# STM32G0B0 register map
File version: 1.0
CPU: CM0 r0p1, little endian, MPU, no FPU, 4 interrupt priority bits
Registers are 32-bit, read-write, reset 0x0 unless marked. A register's access mark holds for its fields unless they carry their own. Offsets are from the block's base; [hi:lo] are bit positions; {n}, {i} and the like mark numbered series; 'fields as' and 'values as' point back to an identical list.

## TIM1 (part 2 of 2) — Advanced-timers
Base 0x40012C00
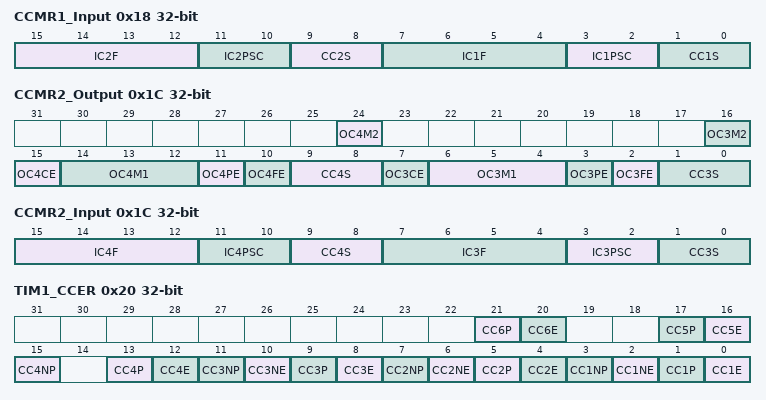
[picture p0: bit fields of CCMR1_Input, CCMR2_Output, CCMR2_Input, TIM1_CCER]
0x18 CCMR1_Input (alternate view of CCMR1_Output) — capture/compare mode register 1 (output mode)
  [15:12] IC2F — Input capture 2 filter Refer to IC1F[3:0] description.
  [11:10] IC2PSC — Input capture 2 prescaler Refer to IC1PSC[1:0] description.
  [9:8] CC2S — Capture/Compare 2 selection This bit-field defines the direction of the channel (input/output) as well as the used input. Note: CC2S bits are writable only when the channel is OFF (CC2E = '0â in TIMx_CCER).
    0=CC2 channel is configured as output; 1=CC2 channel is configured as input, IC2 is mapped on TI2; 2=CC2 channel is configured as input, IC2 is mapped on TI1; 3=CC2 channel is configured as input, IC2 is mapped on TRC. This mode is working only if an internal trigger input is selected through TS bit (TIMx_SMCR register)
  [7:4] IC1F — Input capture 1 filter This bit-field defines the frequency used to sample TI1 input and the length of the digital filter applied to TI1. The digital filter is made of an event counter in which N consecutive events are needed to validate a transition on the output:
    0=No filter, sampling is done at fDTS; 1=fSAMPLING=fCK_INT, N=2; 2=fSAMPLING=fCK_INT, N=4; 3=fSAMPLING=fCK_INT, N=8; 4=fSAMPLING=fDTS/2, N=6; 5=fSAMPLING=fDTS/2, N=8; 6=fSAMPLING=fDTS/4, N=6; 7=fSAMPLING=fDTS/4, N=8; 8=fSAMPLING=fDTS/8, N=6; 9=fSAMPLING=fDTS/8, N=8; 10=fSAMPLING=fDTS/16, N=5; 11=fSAMPLING=fDTS/16, N=6; 12=fSAMPLING=fDTS/16, N=8; 13=fSAMPLING=fDTS/32, N=5; 14=fSAMPLING=fDTS/32, N=6; 15=fSAMPLING=fDTS/32, N=8
  [3:2] IC1PSC — Input capture 1 prescaler This bit-field defines the ratio of the prescaler acting on CC1 input (IC1). The prescaler is reset as soon as CC1E=â0â (TIMx_CCER register).
    0=no prescaler, capture is done each time an edge is detected on the capture input; 1=capture is done once every 2 events; 2=capture is done once every 4 events; 3=capture is done once every 8 events
  [1:0] CC1S — Capture/Compare 1 Selection This bit-field defines the direction of the channel (input/output) as well as the used input. Note: CC1S bits are writable only when the channel is OFF (CC1E = '0â in TIMx_CCER).
    0=CC1 channel is configured as output; 1=CC1 channel is configured as input, IC1 is mapped on TI1; 2=CC1 channel is configured as input, IC1 is mapped on TI2; 3=CC1 channel is configured as input, IC1 is mapped on TRC. This mode is working only if an internal trigger input is selected through TS bit (TIMx_SMCR register)
0x1C CCMR2_Output — capture/compare mode register 2 (output mode)
  [24] OC4M2 — Output compare 4 mode Refer to OC3M[3:0] description.
  [16] OC3M2 — Output compare 3 mode Refer to OC1M[3:0] description.
  [15] OC4CE — Output compare 4 clear enable Refer to OC1CE description.
  [14:12] OC4M1 — Output compare 4 mode Refer to OC3M[3:0] description.
  [11] OC4PE — Output compare 4 preload enable Refer to OC1PE description.
  [10] OC4FE — Output compare 4 fast enable Refer to OC1FE description.
  [9:8] CC4S — Capture/Compare 4 selection This bit-field defines the direction of the channel (input/output) as well as the used input. Note: CC4S bits are writable only when the channel is OFF (CC4E = '0â in TIMx_CCER).
    0=CC4 channel is configured as output; 1=CC4 channel is configured as input, IC4 is mapped on TI4; 2=CC4 channel is configured as input, IC4 is mapped on TI3; 3=CC4 channel is configured as input, IC4 is mapped on TRC. This mode is working only if an internal trigger input is selected through TS bit (TIMx_SMCR register)
  [7] OC3CE — Output compare 3 clear enable Refer to OC1CE description.
  [6:4] OC3M1 — Output compare 3 mode Refer to OC1M[3:0] description.
  [3] OC3PE — Output compare 3 preload enable Refer to OC1PE description.
  [2] OC3FE — Output compare 3 fast enable Refer to OC1FE description.
  [1:0] CC3S — Capture/Compare 3 selection This bit-field defines the direction of the channel (input/output) as well as the used input. Note: CC3S bits are writable only when the channel is OFF (CC3E = '0â in TIMx_CCER).
    0=CC3 channel is configured as output; 1=CC3 channel is configured as input, IC3 is mapped on TI3; 2=CC3 channel is configured as input, IC3 is mapped on TI4; 3=CC3 channel is configured as input, IC3 is mapped on TRC. This mode is working only if an internal trigger input is selected through TS bit (TIMx_SMCR register)
0x1C CCMR2_Input (alternate view of CCMR2_Output) — capture/compare mode register 2 (output mode)
  [15:12] IC4F — Input capture 4 filter Refer to IC1F[3:0] description.
  [11:10] IC4PSC — Input capture 4 prescaler Refer to IC1PSC[1:0] description.
  [9:8] CC4S — Capture/Compare 4 selection This bit-field defines the direction of the channel (input/output) as well as the used input. Note: CC4S bits are writable only when the channel is OFF (CC4E = '0â in TIMx_CCER).
    values as CCMR2_Output.CC4S
  [7:4] IC3F — Input capture 3 filter Refer to IC1F[3:0] description.
  [3:2] IC3PSC — Input capture 3 prescaler Refer to IC1PSC[1:0] description.
  [1:0] CC3S — Capture/compare 3 selection This bit-field defines the direction of the channel (input/output) as well as the used input. Note: CC3S bits are writable only when the channel is OFF (CC3E = '0â in TIMx_CCER).
    values as CCMR2_Output.CC3S
0x20 TIM1_CCER — capture/compare enable register
  [4n-3] CC{n}P (n=2..6) — Capture/Compare {n} output polarity Refer to CC1P description
  [4n-4] CC{n}E (n=2..6) — Capture/Compare {n} output enable Refer to CC1E description
  [15] CC4NP — Capture/Compare 4 complementary output polarity Refer to CC1NP description
  [11] CC3NP — Capture/Compare 3 complementary output polarity Refer to CC1NP description
  [10] CC3NE — Capture/Compare 3 complementary output enable Refer to CC1NE description
  [7] CC2NP — Capture/Compare 2 complementary output polarity Refer to CC1NP description
  [6] CC2NE — Capture/Compare 2 complementary output enable Refer to CC1NE description
  [3] CC1NP — Capture/Compare 1 complementary output polarity CC1 channel configured as output: CC1 channel configured as input: This bit is used in conjunction with CC1P to define the polarity of TI1FP1 and TI2FP1. Refer to CC1P description. Note: This bit is not writable as soon as LOCK level 2 or 3 has been programmed (LOCK bits in TIMx_BDTR register) and CC1S=â00â (channel configured as output). On channels having a complementary output, this bit is preloaded. If the CCPC bit is set in the TIMx_CR2 register then the CC1NP active bit takes the new value from the preloaded bit only when a Commutation event is generated.
    0=OC1N active high; 1=OC1N active low
  [2] CC1NE — Capture/Compare 1 complementary output enable On channels having a complementary output, this bit is preloaded. If the CCPC bit is set in the TIMx_CR2 register then the CC1NE active bit takes the new value from the preloaded bit only when a Commutation event is generated.
    0=Off - OC1N is not active. OC1N level is then function of MOE, OSSI, OSSR, OIS1, OIS1N and CC1E bits.; 1=On - OC1N signal is output on the corresponding output pin depending on MOE, OSSI, OSSR, OIS1, OIS1N and CC1E bits
  [1] CC1P — Capture/Compare 1 output polarity When CC1 channel is configured as input, both CC1NP/CC1P bits select the active polarity of TI1FP1 and TI2FP1 for trigger or capture operations. CC1NP=0, CC1P=0: non-inverted/rising edge. The circuit is sensitive to TIxFP1 rising edge (capture or trigger operations in reset, external clock or trigger mode), TIxFP1 is not inverted (trigger operation in gated mode or encoder mode). CC1NP=0, CC1P=1: inverted/falling edge. The circuit is sensitive to TIxFP1 falling edge (capture or trigger operations in reset, external clock or trigger mode), TIxFP1 is inverted (trigger operation in gated mode or encoder mode). CC1NP=1, CC1P=1: non-inverted/both edges/ The circuit is sensitive to both TIxFP1 rising and falling edges (capture or trigger operations in reset, external clock or trigger mode), TIxFP1is not inverted (trigger operation in gated mode). This configuration must not be used in encoder mode. CC1NP=1, CC1P=0: The configuration is reserved, it must not be used. Note: This bit is not writable as soon as LOCK level 2 or 3 has been programmed (LOCK bits in TIMx_BDTR register). On channels having a complementary output, this bit is preloaded. If the CCPC bit is set in the TIMx_CR2 register then the CC1P active bit takes the new value from the preloaded bit only when a Commutation event is generated.
    0=OC1 active high (output mode) / Edge sensitivity selection (input mode, see below); 1=OC1 active low (output mode) / Edge sensitivity selection (input mode, see below)
  [0] CC1E — Capture/Compare 1 output enable When CC1 channel is configured as output, the OC1 level depends on MOE, OSSI, OSSR, OIS1, OIS1N and CC1NE bits, regardless of the CC1E bits state. Refer to for details. Note: On channels having a complementary output, this bit is preloaded. If the CCPC bit is set in the TIMx_CR2 register then the CC1E active bit takes the new value from the preloaded bit only when a Commutation event is generated.
    0=Capture mode disabled / OC1 is not active (see below); 1=Capture mode enabled / OC1 signal is output on the corresponding output pin
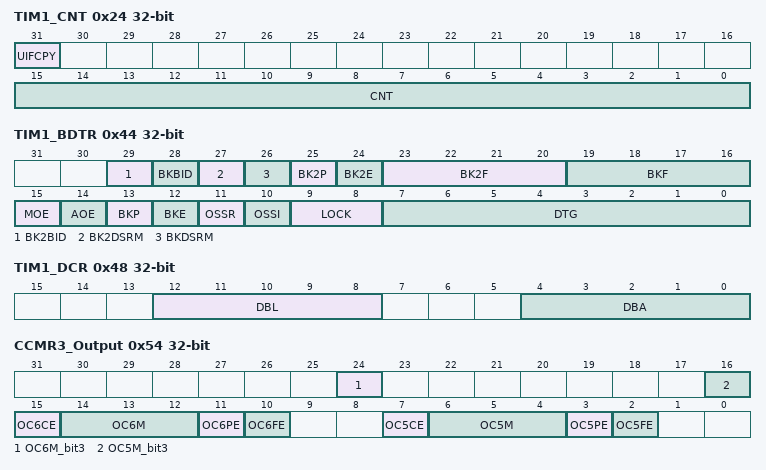
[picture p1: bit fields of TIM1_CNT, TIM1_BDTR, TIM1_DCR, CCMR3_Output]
0x24 TIM1_CNT access per field — counter
  [31] UIFCPY ro — UIF copy This bit is a read-only copy of the UIF bit of the TIMx_ISR register. If the UIFREMAP bit in the TIMxCR1 is reset, bit 31 is reserved and read at 0.
  [15:0] CNT rw — Counter value
0x28 TIM1_PSC — prescaler
  [15:0] PSC — Prescaler value The counter clock frequency (CK_CNT) is equal to fCK_PSC / (PSC[15:0] + 1). PSC contains the value to be loaded in the active prescaler register at each update event (including when the counter is cleared through UG bit of TIMx_EGR register or through trigger controller when configured in âreset modeâ).
0x2C TIM1_ARR reset 0xFFFF — auto-reload register
  [15:0] ARR — Auto-reload value ARR is the value to be loaded in the actual auto-reload register. Refer to the for more details about ARR update and behavior. The counter is blocked while the auto-reload value is null.
0x30 TIM1_RCR — repetition counter register
  [15:0] REP — Repetition counter value
0x34 TIM1_CCR1 — capture/compare register 1
  [15:0] CCR1 — Capture/Compare 1 value
0x38 TIM1_CCR2 — capture/compare register 2
  [15:0] CCR2 — Capture/Compare 2 value
0x3C TIM1_CCR3 — capture/compare register 3
  [15:0] CCR3 — Capture/Compare value
0x40 TIM1_CCR4 — capture/compare register 4
  [15:0] CCR4 — Capture/Compare value
0x44 TIM1_BDTR — break and dead-time register
  [29] BK2BID — Break2 bidirectional Refer to BKBID description
  [28] BKBID — Break Bidirectional In the bidirectional mode (BKBID bit set to 1), the break input is configured both in input mode and in open drain output mode. Any active break event asserts a low logic level on the Break input to indicate an internal break event to external devices. Note: This bit cannot be modified as long as LOCK level 1 has been programmed (LOCK bits in TIMx_BDTR register). Note: Any write operation to this bit takes a delay of 1 APB clock cycle to become effective.
    0=Break input BRK in input mode; 1=Break input BRK in bidirectional mode
  [27] BK2DSRM — Break2 Disarm Refer to BKDSRM description
  [26] BKDSRM — Break Disarm This bit is cleared by hardware when no break source is active. The BKDSRM bit must be set by software to release the bidirectional output control (open-drain output in Hi-Z state) and then be polled it until it is reset by hardware, indicating that the fault condition has disappeared. Note: Any write operation to this bit takes a delay of 1 APB clock cycle to become effective.
    0=Break input BRK is armed; 1=Break input BRK is disarmed
  [25] BK2P — Break 2 polarity Note: This bit cannot be modified as long as LOCK level 1 has been programmed (LOCK bits in TIMx_BDTR register). Note: Any write operation to this bit takes a delay of 1 APB clock cycle to become effective.
    0=Break input BRK2 is active low; 1=Break input BRK2 is active high
  [24] BK2E — Break 2 enable Note: The BRK2 must only be used with OSSR = OSSI = 1. Note: This bit cannot be modified when LOCK level 1 has been programmed (LOCK bits in TIMx_BDTR register). Note: Any write operation to this bit takes a delay of 1 APB clock cycle to become effective.
    0=Break input BRK2 disabled; 1=Break input BRK2 enabled
  [23:20] BK2F — Break 2 filter This bit-field defines the frequency used to sample BRK2 input and the length of the digital filter applied to BRK2. The digital filter is made of an event counter in which N consecutive events are needed to validate a transition on the output: Note: This bit cannot be modified when LOCK level 1 has been programmed (LOCK bits in TIMx_BDTR register).
    0=No filter, BRK2 acts asynchronously; 1=fSAMPLING=fCK_INT, N=2; 2=fSAMPLING=fCK_INT, N=4; 3=fSAMPLING=fCK_INT, N=8; 4=fSAMPLING=fDTS/2, N=6; 5=fSAMPLING=fDTS/2, N=8; 6=fSAMPLING=fDTS/4, N=6; 7=fSAMPLING=fDTS/4, N=8; 8=fSAMPLING=fDTS/8, N=6; 9=fSAMPLING=fDTS/8, N=8; 10=fSAMPLING=fDTS/16, N=5; 11=fSAMPLING=fDTS/16, N=6; 12=fSAMPLING=fDTS/16, N=8; 13=fSAMPLING=fDTS/32, N=5; 14=fSAMPLING=fDTS/32, N=6; 15=fSAMPLING=fDTS/32, N=8
  [19:16] BKF — Break filter This bit-field defines the frequency used to sample BRK input and the length of the digital filter applied to BRK. The digital filter is made of an event counter in which N consecutive events are needed to validate a transition on the output: Note: This bit cannot be modified when LOCK level 1 has been programmed (LOCK bits in TIMx_BDTR register).
    0=No filter, BRK acts asynchronously; 1=fSAMPLING=fCK_INT, N=2; 2=fSAMPLING=fCK_INT, N=4; 3=fSAMPLING=fCK_INT, N=8; 4=fSAMPLING=fDTS/2, N=6; 5=fSAMPLING=fDTS/2, N=8; 6=fSAMPLING=fDTS/4, N=6; 7=fSAMPLING=fDTS/4, N=8; 8=fSAMPLING=fDTS/8, N=6; 9=fSAMPLING=fDTS/8, N=8; 10=fSAMPLING=fDTS/16, N=5; 11=fSAMPLING=fDTS/16, N=6; 12=fSAMPLING=fDTS/16, N=8; 13=fSAMPLING=fDTS/32, N=5; 14=fSAMPLING=fDTS/32, N=6; 15=fSAMPLING=fDTS/32, N=8
  [15] MOE — Main output enable This bit is cleared asynchronously by hardware as soon as one of the break inputs is active (BRK or BRK2). It is set by software or automatically depending on the AOE bit. It is acting only on the channels which are configured in output. In response to a break event or if MOE is written to 0: OC and OCN outputs are disabled or forced to idle state depending on the OSSI bit. See OC/OCN enable description for more details (enable register (TIM1_CCERTIMx_CCER)N/A).
    0=In response to a break 2 event. OC and OCN outputs are disabled; 1=OC and OCN outputs are enabled if their respective enable bits are set (CCxE, CCxNE in TIMx_CCER register)
  [14] AOE — Automatic output enable Note: This bit can not be modified as long as LOCK level 1 has been programmed (LOCK bits in TIMx_BDTR register).
    0=MOE can be set only by software; 1=MOE can be set by software or automatically at the next update event (if none of the break inputs BRK and BRK2 is active)
  [13] BKP — Break polarity Note: This bit can not be modified as long as LOCK level 1 has been programmed (LOCK bits in TIMx_BDTR register). Note: Any write operation to this bit takes a delay of 1 APB clock cycle to become effective.
    0=Break input BRK is active low; 1=Break input BRK is active high
  [12] BKE — Break enable This bit enables the complete break protection (including all sources connected to bk_acth and BKIN sources, as per ). Note: This bit cannot be modified when LOCK level 1 has been programmed (LOCK bits in TIMx_BDTR register). Note: Any write operation to this bit takes a delay of 1 APB clock cycle to become effective.
    0=Break function disabled; 1=Break function enabled
  [11] OSSR — Off-state selection for Run mode This bit is used when MOE=1 on channels having a complementary output which are configured as outputs. OSSR is not implemented if no complementary output is implemented in the timer. See OC/OCN enable description for more details (enable register (TIM1_CCERTIMx_CCER)N/A). Note: This bit can not be modified as soon as the LOCK level 2 has been programmed (LOCK bits in TIMx_BDTR register).
    0=When inactive, OC/OCN outputs are disabled (the timer releases the output control which is taken over by the GPIO logic, which forces a Hi-Z state); 1=When inactive, OC/OCN outputs are enabled with their inactive level as soon as CCxE=1 or CCxNE=1 (the output is still controlled by the timer)
  [10] OSSI — Off-state selection for Idle mode This bit is used when MOE=0 due to a break event or by a software write, on channels configured as outputs. See OC/OCN enable description for more details (enable register (TIM1_CCERTIMx_CCER)N/A). Note: This bit can not be modified as soon as the LOCK level 2 has been programmed (LOCK bits in TIMx_BDTR register).
    0=When inactive, OC/OCN outputs are disabled (the timer releases the output control which is taken over by the GPIO logic and which imposes a Hi-Z state); 1=When inactive, OC/OCN outputs are first forced with their inactive level then forced to their idle level after the deadtime. The timer maintains its control over the output.
  [9:8] LOCK — Lock configuration These bits offer a write protection against software errors. Note: The LOCK bits can be written only once after the reset. Once the TIMx_BDTR register has been written, their content is frozen until the next reset.
    0=LOCK OFF - No bit is write protected; 1=LOCK Level 1 = DTG bits in TIMx_BDTR register, OISx and OISxN bits in TIMx_CR2 register and BK2BID, BKBID, BK2DSRM, BKDSRM, BK2P, BK2E, BK2F[3:0], BKF[3:0], AOE, BKP, BKE, OSSI, OSSR and DTG[7:0] bits in TIMx_BDTR register can no longer be written; 2=LOCK Level 2 = LOCK Level 1 + CC Polarity bits (CCxP/CCxNP bits in TIMx_CCER register, as long as the related channel is configured in output through the CCxS bits) as well as OSSR and OSSI bits can no longer be written; 3=LOCK Level 3 = LOCK Level 2 + CC Control bits (OCxM and OCxPE bits in TIMx_CCMRx registers, as long as the related channel is configured in output through the CCxS bits) can no longer be written
  [7:0] DTG — Dead-time generator setup This bit-field defines the duration of the dead-time inserted between the complementary outputs. DT correspond to this duration. DTG[7:5]=0xx => DT=DTG[7:0]x tDTG with tDTG=tDTS. DTG[7:5]=10x => DT=(64+DTG[5:0])xtDTG with tDTG=2xtDTS. DTG[7:5]=110 => DT=(32+DTG[4:0])xtDTG with tDTG=8xtDTS. DTG[7:5]=111 => DT=(32+DTG[4:0])xtDTG with tDTG=16xtDTS. Example if tDTS=125Â ns (8Â MHz), dead-time possible values are: 0 to 15875Â ns by 125Â ns steps, 16Â Î¼s to 31750Â nsÂ by 250Â ns steps, 32Â Î¼s to 63Â Î¼s by 1Â Î¼s steps, 64Â Î¼s to 126Â Î¼s by 2Â Î¼s steps Note: This bit-field can not be modified as long as LOCK level 1, 2 or 3 has been programmed (LOCK bits in TIMx_BDTR register).
0x48 TIM1_DCR — DMA control register
  [12:8] DBL — DMA burst length This 5-bit vector defines the length of DMA transfers (the timer recognizes a burst transfer when a read or a write access is done to the TIMx_DMAR address), i.e. the number of transfers. Transfers can be in half-words or in bytes (see example below). ... Example: Let us consider the following transfer: DBL = 7 bytes & DBA = TIMx_CR1. If DBL = 7 bytes and DBA = TIMx_CR1 represents the address of the byte to be transferred, the address of the transfer should be given by the following equation: (TIMx_CR1 address) + DBA + (DMA index), where DMA index = DBL In this example, 7 bytes are added to (TIMx_CR1 address) + DBA, which gives us the address from/to which the data is copied. In this case, the transfer is done to 7 registers starting from the following address: (TIMx_CR1 address) + DBA According to the configuration of the DMA Data Size, several cases may occur: If the DMA Data Size is configured in half-words, 16-bit data is transferred to each of the 7 registers. If the DMA Data Size is configured in bytes, the data is also transferred to 7 registers: the first register contains the first MSB byte, the second register, the first LSB byte and so on. So with the transfer Timer, one also has to specify the size of data transferred by DMA.
    0=1 transfer; 1=2 transfers; 2=3 transfers; 17=18 transfers
  [4:0] DBA — DMA base address This 5-bits vector defines the base-address for DMA transfers (when read/write access are done through the TIMx_DMAR address). DBA is defined as an offset starting from the address of the TIMx_CR1 register. Example: ...
    0=TIMx_CR1,; 1=TIMx_CR2,; 2=TIMx_SMCR,
0x4C TIM1_DMAR — DMA address for full transfer
  [31:0] DMAB — DMA register for burst accesses A read or write operation to the DMAR register accesses the register located at the address (TIMx_CR1 address) + (DBA + DMA index) x 4 where TIMx_CR1 address is the address of the control register 1, DBA is the DMA base address configured in TIMx_DCR register, DMA index is automatically controlled by the DMA transfer, and ranges from 0 to DBL (DBL configured in TIMx_DCR).
0x50 TIM1_OR1 — option register 1
  [0] OCREF_CLR — Ocref_clr source selection This bit selects the ocref_clr input source.
    0=COMP1 output is connected to the OCREF_CLR input; 1=COMP2 output is connected to the OCREF_CLR input
0x54 CCMR3_Output — capture/compare mode register 2 (output mode)
  [24] OC6M_bit3 — Output Compare 6 mode bit 3
  [16] OC5M_bit3 — Output Compare 5 mode bit 3
  [15] OC6CE — Output compare 6 clear enable
  [14:12] OC6M — Output compare 6 mode
  [11] OC6PE — Output compare 6 preload enable
  [10] OC6FE — Output compare 6 fast enable
  [7] OC5CE — Output compare 5 clear enable
  [6:4] OC5M — Output compare 5 mode
  [3] OC5PE — Output compare 5 preload enable
  [2] OC5FE — Output compare 5 fast enable
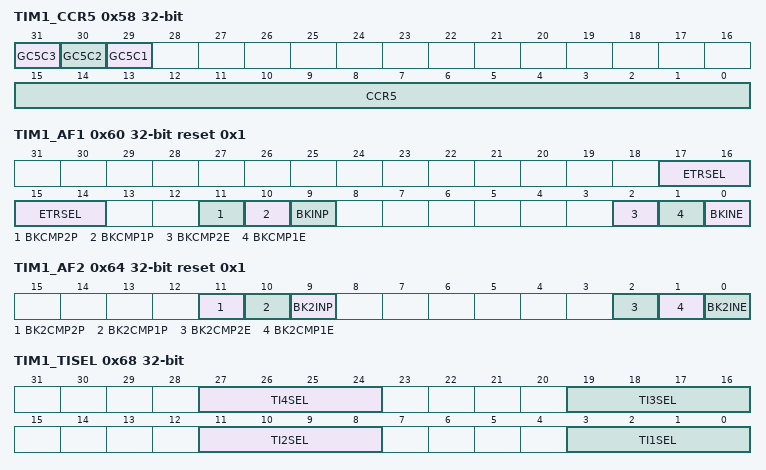
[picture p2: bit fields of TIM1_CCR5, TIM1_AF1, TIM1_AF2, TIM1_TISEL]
0x58 TIM1_CCR5 — capture/compare register 4
  [31] GC5C3 — Group Channel 5 and Channel 3 Distortion on Channel 3 output: This bit can either have immediate effect or be preloaded and taken into account after an update event (if preload feature is selected in TIMxCCMR2). Note: it is also possible to apply this distortion on combined PWM signals.
    0=No effect of OC5REF on OC3REFC; 1=OC3REFC is the logical AND of OC3REFC and OC5REF
  [30] GC5C2 — Group Channel 5 and Channel 2 Distortion on Channel 2 output: This bit can either have immediate effect or be preloaded and taken into account after an update event (if preload feature is selected in TIMxCCMR1). Note: it is also possible to apply this distortion on combined PWM signals.
    0=No effect of OC5REF on OC2REFC; 1=OC2REFC is the logical AND of OC2REFC and OC5REF
  [29] GC5C1 — Group Channel 5 and Channel 1 Distortion on Channel 1 output: This bit can either have immediate effect or be preloaded and taken into account after an update event (if preload feature is selected in TIMxCCMR1). Note: it is also possible to apply this distortion on combined PWM signals.
    0=No effect of OC5REF on OC1REFC5; 1=OC1REFC is the logical AND of OC1REFC and OC5REF
  [15:0] CCR5 — Capture/Compare 5 value CCR5 is the value to be loaded in the actual capture/compare 5 register (preload value). It is loaded permanently if the preload feature is not selected in the TIMx_CCMR3 register (bit OC5PE). Else the preload value is copied in the active capture/compare 5 register when an update event occurs. The active capture/compare register contains the value to be compared to the counter TIMx_CNT and signaled on OC5 output.
0x5C TIM1_CCR6 — capture/compare register 4
  [15:0] CCR6 — Capture/Compare value
0x60 TIM1_AF1 reset 0x1 — DMA address for full transfer
  [17:14] ETRSEL — ETR source selection These bits select the ETR input source. Others: Reserved Note: These bits can not be modified as long as LOCK level 1 has been programmed (LOCK bits in TIMx_BDTR register).
    0=ETR legacy mode; 1=COMP1 output; 2=COMP2 output; 3=ADC1 AWD1; 4=ADC1 AWD2; 5=ADC1 AWD3
  [11] BKCMP2P — BRK COMP2 input polarity This bit selects the COMP2 input sensitivity. It must be programmed together with the BKP polarity bit. Note: This bit can not be modified as long as LOCK level 1 has been programmed (LOCK bits in TIMx_BDTR register).
    0=COMP2 input polarity is not inverted (active low if BKP=0, active high if BKP=1); 1=COMP2 input polarity is inverted (active high if BKP=0, active low if BKP=1)
  [10] BKCMP1P — BRK COMP1 input polarity This bit selects the COMP1 input sensitivity. It must be programmed together with the BKP polarity bit. Note: This bit can not be modified as long as LOCK level 1 has been programmed (LOCK bits in TIMx_BDTR register).
    0=COMP1 input polarity is not inverted (active low if BKP=0, active high if BKP=1); 1=COMP1 input polarity is inverted (active high if BKP=0, active low if BKP=1)
  [9] BKINP — BRK BKIN input polarity This bit selects the BKIN alternate function input sensitivity. It must be programmed together with the BKP polarity bit. Note: This bit can not be modified as long as LOCK level 1 has been programmed (LOCK bits in TIMx_BDTR register).
    0=BKIN input polarity is not inverted (active low if BKP=0, active high if BKP=1); 1=BKIN input polarity is inverted (active high if BKP=0, active low if BKP=1)
  [2] BKCMP2E — BRK COMP2 enable This bit enables the COMP2 for the timerâs BRK input. COMP2 output is 'ORedâ with the other BRK sources. Note: This bit can not be modified as long as LOCK level 1 has been programmed (LOCK bits in TIMx_BDTR register).
    0=COMP2 input disabled; 1=COMP2 input enabled
  [1] BKCMP1E — BRK COMP1 enable This bit enables the COMP1 for the timerâs BRK input. COMP1 output is 'ORedâ with the other BRK sources. Note: This bit can not be modified as long as LOCK level 1 has been programmed (LOCK bits in TIMx_BDTR register).
    0=COMP1 input disabled; 1=COMP1 input enabled
  [0] BKINE — BRK BKIN input enable This bit enables the BKIN alternate function input for the timerâs BRK input. BKIN input is 'ORedâ with the other BRK sources. Note: This bit can not be modified as long as LOCK level 1 has been programmed (LOCK bits in TIMx_BDTR register).
    0=BKIN input disabled; 1=BKIN input enabled
0x64 TIM1_AF2 reset 0x1 — DMA address for full transfer
  [11] BK2CMP2P — BRK2 COMP2 input polarity This bit selects the COMP2 input sensitivity. It must be programmed together with the BK2P polarity bit. Note: This bit can not be modified as long as LOCK level 1 has been programmed (LOCK bits in TIMx_BDTR register).
    0=COMP2 input polarity is not inverted (active low if BK2P=0, active high if BK2P=1); 1=COMP2 input polarity is inverted (active high if BK2P=0, active low if BK2P=1)
  [10] BK2CMP1P — BRK2 COMP1 input polarity This bit selects the COMP1 input sensitivity. It must be programmed together with the BK2P polarity bit. Note: This bit can not be modified as long as LOCK level 1 has been programmed (LOCK bits in TIMx_BDTR register).
    0=COMP1 input polarity is not inverted (active low if BK2P=0, active high if BK2P=1); 1=COMP1 input polarity is inverted (active high if BK2P=0, active low if BK2P=1)
  [9] BK2INP — BRK2 BKIN2 input polarity This bit selects the BKIN2 alternate function input sensitivity. It must be programmed together with the BK2P polarity bit. Note: This bit can not be modified as long as LOCK level 1 has been programmed (LOCK bits in TIMx_BDTR register).
    0=BKIN2 input polarity is not inverted (active low if BK2P=0, active high if BK2P=1); 1=BKIN2 input polarity is inverted (active high if BK2P=0, active low if BK2P=1)
  [2] BK2CMP2E — BRK2 COMP2 enable This bit enables the COMP2 for the timerâs BRK2 input. COMP2 output is 'ORedâ with the other BRK2 sources. Note: This bit can not be modified as long as LOCK level 1 has been programmed (LOCK bits in TIMx_BDTR register).
    0=COMP2 input disabled; 1=COMP2 input enabled
  [1] BK2CMP1E — BRK2 COMP1 enable This bit enables the COMP1 for the timerâs BRK2 input. COMP1 output is 'ORedâ with the other BRK2 sources. Note: This bit can not be modified as long as LOCK level 1 has been programmed (LOCK bits in TIMx_BDTR register).
    0=COMP1 input disabled; 1=COMP1 input enabled
  [0] BK2INE — BRK2 BKIN input enable This bit enables the BKIN2 alternate function input for the timerâs BRK2 input. BKIN2 input is 'ORedâ with the other BRK2 sources. Note: This bit can not be modified as long as LOCK level 1 has been programmed (LOCK bits in TIMx_BDTR register).
    0=BKIN2 input disabled; 1=BKIN2 input enabled
0x68 TIM1_TISEL — TIM1 timer input selection register
  [27:24] TI4SEL — selects TI4[0] to TI4[15] input Others: Reserved
    0=TIM1_CH4 input
  [19:16] TI3SEL — selects TI3[0] to TI3[15] input Others: Reserved
    0=TIM1_CH3 input
  [11:8] TI2SEL — selects TI2[0] to TI2[15] input Others: Reserved
    0=TIM1_CH2 input; 1=COMP2 output
  [3:0] TI1SEL — selects TI1[0] to TI1[15] input Others: Reserved
    0=TIM1_CH1 input; 1=COMP1 output
